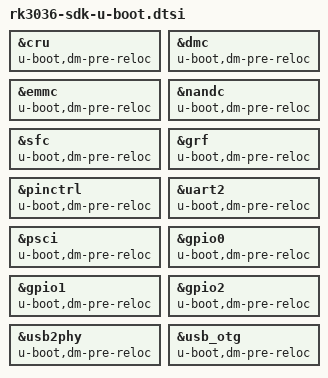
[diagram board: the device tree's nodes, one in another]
&cru {
	u-boot,dm-pre-reloc;
};

&dmc {
	u-boot,dm-pre-reloc;
};

&emmc {
	u-boot,dm-pre-reloc;
};

&nandc {
	u-boot,dm-pre-reloc;
	status = "okay";
};

&sfc {
	u-boot,dm-pre-reloc;
	status = "okay";
};

&grf {
	u-boot,dm-pre-reloc;
};

&pinctrl {
	u-boot,dm-pre-reloc;
};

&uart2 {
	u-boot,dm-pre-reloc;
};

&psci {
	u-boot,dm-pre-reloc;
	status = "okay";
};

&pinctrl {
	u-boot,dm-pre-reloc;
	status = "okay";
};

&gpio0 {
	u-boot,dm-pre-reloc;
	status = "okay";
};

&gpio1 {
	u-boot,dm-pre-reloc;
	status = "okay";
};

&gpio2 {
	u-boot,dm-pre-reloc;
	status = "okay";
};

&usb2phy {
	u-boot,dm-pre-reloc;
	status = "okay";
};

&usb_otg {
	u-boot,dm-pre-reloc;
};
